# PIC32CM1216LS00064 device description
Architecture: CORTEX-M23; Family: PIC32CM; Series: PIC32CMLS00
Registers are 32-bit, read-write, reset 0x0 unless marked. A register's access mark holds for its fields unless they carry their own. Offsets are from the block's base; [hi:lo] are bit positions; {n}, {i} and the like mark numbered series; 'fields as' and 'values as' point back to an identical list; <NAME> marks a mode.

## DAC — Digital-to-Analog Converter
Instances: DAC 0x42003C00
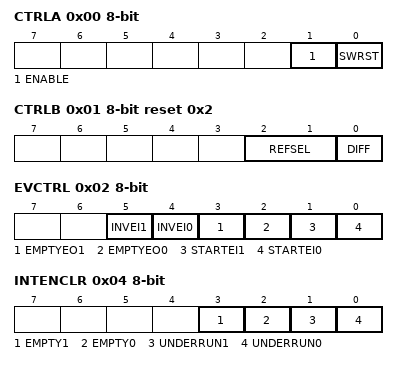
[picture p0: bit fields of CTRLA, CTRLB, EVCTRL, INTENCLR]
0x00 CTRLA 8-bit (WSYNC) — Control A
  [1] ENABLE — Enable DAC Controller
  [0] SWRST — Software Reset
0x01 CTRLB 8-bit reset 0x2 — Control B
  [2:1] REFSEL — Reference Selection for DAC0/1
    0=VREFAU (Unbuffered External Voltage Reference (not buffered in DAC, direct connection)); 1=VDDANA (Analog Voltage Supply); 2=VREFAB (Buffered External Voltage Reference (buffered in DAC)); 3=INTREF (Internal Voltage Reference)
  [0] DIFF — Differential mode enable
0x02 EVCTRL 8-bit — Event Control
  [5] INVEI1 — Enable Invertion of DAC 1 input event
  [4] INVEI0 — Enable Invertion of DAC 0 input event
  [3] EMPTYEO1 — Data Buffer Empty Event Output DAC 1
  [2] EMPTYEO0 — Data Buffer Empty Event Output DAC 0
  [1] STARTEI1 — Start Conversion Event Input DAC 1
  [0] STARTEI0 — Start Conversion Event Input DAC 0
0x04 INTENCLR 8-bit (atomic clear) — Interrupt Enable Clear
  [3] EMPTY1 — Data Buffer 1 Empty Interrupt Enable
  [2] EMPTY0 — Data Buffer 0 Empty Interrupt Enable
  [1] UNDERRUN1 — Underrun Interrupt Enable for DAC 1
  [0] UNDERRUN0 — Underrun Interrupt Enable for DAC 0
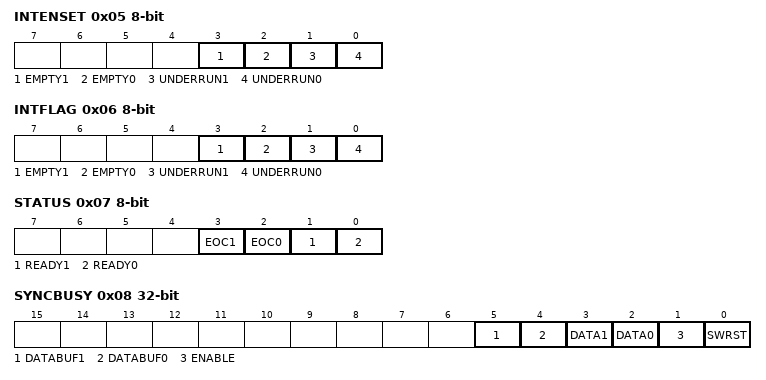
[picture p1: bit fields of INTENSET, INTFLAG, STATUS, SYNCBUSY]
0x05 INTENSET 8-bit (atomic set) — Interrupt Enable Set
  fields as INTENCLR
0x06 INTFLAG 8-bit (atomic clear) — Interrupt Flag Status and Clear
  [3] EMPTY1 — Data Buffer 1 Empty
  [2] EMPTY0 — Data Buffer 0 Empty
  [1] UNDERRUN1 — DAC 1 Underrun
  [0] UNDERRUN0 — DAC 0 Underrun
0x07 STATUS 8-bit ro
  [3] EOC1 — DAC 1 End of Conversion
  [2] EOC0 — DAC 0 End of Conversion
  [1] READY1 — DAC 1 Startup Ready
  [0] READY0 — DAC 0 Startup Ready
0x08 SYNCBUSY ro — Synchronization Busy
  [5] DATABUF1 — Data Buffer DAC 1
  [4] DATABUF0 — Data Buffer DAC 0
  [3] DATA1 — Data DAC 1
  [2] DATA0 — Data DAC 0
  [1] ENABLE — DAC Enable Status
  [0] SWRST — Software Reset
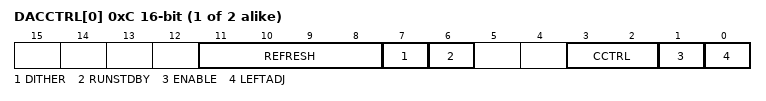
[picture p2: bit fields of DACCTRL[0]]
{0xC+2i} DACCTRL[{i}] (i=0..1) 16-bit — DAC n Control
  [11:8] REFRESH — Refresh period
    0=Do not Refresh; 2=Refresh every 60US; 3=Refresh every 90US; 4=Refresh every 120US; 5=Refresh every 150US; 6=Refresh every 180US; 7=Refresh every 210US; 8=Refresh every 240US; 9=Refresh every 270US; 10=Refresh every 300US; 11=Refresh every 330US; 12=Refresh every 360US; 13=Refresh every 390US; 14=Refresh every 420US; 15=Refresh every 450US
  [7] DITHER — Dithering Mode
  [6] RUNSTDBY — Run in Standby
  [3:2] CCTRL — Current Control
    0=CC100K (GCLK_DAC <= 1.2MHz (100kSPS)); 1=CC1M (1.2MHz < GCLK_DAC <= 6MHz (500kSPS)); 2=CC12M (6MHz < GCLK_DAC <= 12MHz (1MSPS))
  [1] ENABLE — Enable DAC0
  [0] LEFTADJ — Left Adjusted Data
{0x10+2i} DATA[{i}] (i=0..1) 16-bit wo (WSYNC) — DAC n Data
  [15:0] DATA — DAC0 Data
{0x14+2i} DATABUF[{i}] (i=0..1) 16-bit wo (WSYNC) — DAC n Data Buffer
  [15:0] DATABUF — DAC0 Data Buffer
0x18 DBGCTRL 8-bit — Debug Control
  [0] DBGRUN — Debug Run

## DIB — Debug Identification Block
Instances: DIB 0xE000EFB0, DIB_NS 0xE002EFB0
0x00 DLAR wo reset not defined — SCS Software Lock Access Register
  [31:0] KEY — Lock access control
    0xC5ACCE55=UNLOCK (Unlock key value)
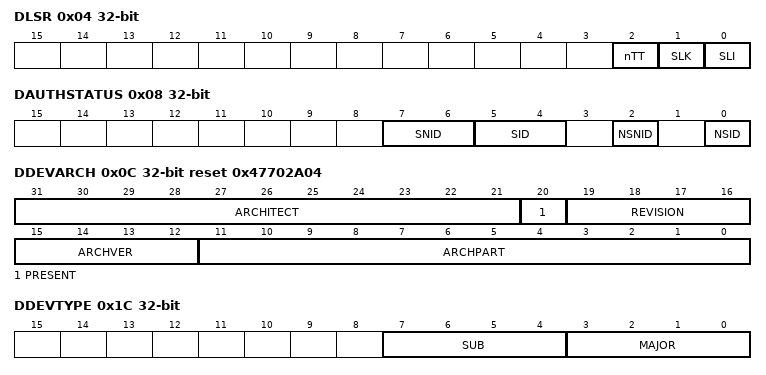
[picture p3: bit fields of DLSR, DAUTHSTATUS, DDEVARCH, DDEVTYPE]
0x04 DLSR ro reset not defined — SCS Software Lock Status Register
  [2] nTT — Not thirty-two bit
  [1] SLK — Software Lock status
  [0] SLI — Software Lock implemented
0x08 DAUTHSTATUS ro reset not defined — Debug Authentication Status Register
  [7:6] SNID
    0=NOSEC (Security Extension not implemented); 2=NO (Secure non-invasive debug prohibited); 3=YES (Secure non-invasive debug allowed)
  [5:4] SID
    0=NOSEC (Security Extension not implemented); 2=NO (Secure invasive debug prohibited); 3=YES (Secure invasive debug allowed)
  [2] NSNID
    2=NO (Non-secure non-invasive debug prohibited); 3=YES (Non-secure non-invasive debug allowed)
  [0] NSID
    2=NO (Non-secure invasive debug prohibited); 3=YES (Non-secure invasive debug allowed)
0x0C DDEVARCH ro reset 0x47702A04 — SCS Device Architecture Register
  [31:21] ARCHITECT
  [20] PRESENT — DEVARCH Present
  [19:16] REVISION
  [15:12] ARCHVER — Architecture Version
  [11:0] ARCHPART — Architecture Part
0x1C DDEVTYPE ro — SCS Device Type Register
  [7:4] SUB — Sub-type
  [3:0] MAJOR — Major type
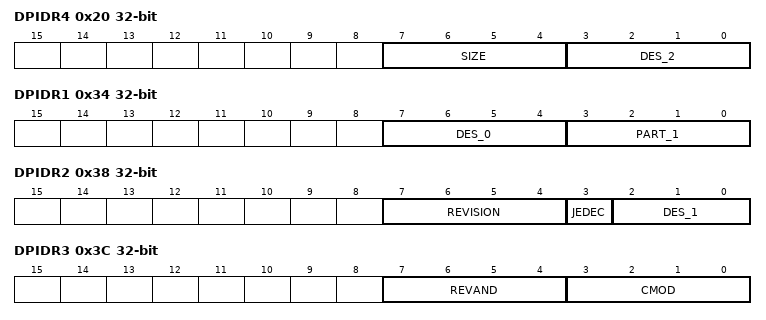
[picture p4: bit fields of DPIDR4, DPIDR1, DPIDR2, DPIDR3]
0x20 DPIDR4 ro reset not defined — SCS Peripheral Identification Register 4
  [7:4] SIZE — 4KB count
  [3:0] DES_2 — JEP106 continuation code
{0x10+4i} DPIDR{i} ro (i=5..7) — SCS Peripheral Identification Register {i}
0x30 DPIDR0 ro reset not defined — SCS Peripheral Identification Register 0
  [7:0] PART_0 — Part number bits[7:0]
0x34 DPIDR1 ro reset not defined — SCS Peripheral Identification Register 1
  [7:4] DES_0 — JEP106 identification code bits [3:0]
  [3:0] PART_1 — Part number bits[11:8]
0x38 DPIDR2 ro reset not defined — SCS Peripheral Identification Register 2
  [7:4] REVISION — Component revision
  [3] JEDEC — JEDEC assignee value is used
  [2:0] DES_1 — JEP106 identification code bits[6:4]
0x3C DPIDR3 ro reset not defined — SCS Peripheral Identification Register 3
  [7:4] REVAND
  [3:0] CMOD — Customer Modified
0x40 DCIDR0 ro reset 0xD — SCS Component Identification Register 0
  [7:0] PRMBL_0 — CoreSight component identification preamble
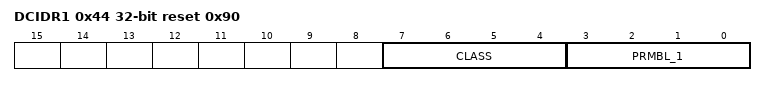
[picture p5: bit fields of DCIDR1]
0x44 DCIDR1 ro reset 0x90 — SCS Component Identification Register 1
  [7:4] CLASS — CoreSight component class
  [3:0] PRMBL_1 — CoreSight component identification preamble
0x48 DCIDR2 ro reset 0x5 — SCS Component Identification Register 2
  [7:0] PRMBL_2 — CoreSight component identification preamble
0x4C DCIDR3 ro reset 0xB1 — SCS Component Identification Register 3
  [7:0] PRMBL_3 — CoreSight component identification preamble

## Notices in the file
Copyright (c) 2019 Microchip Technology Inc.
SPDX-License-Identifier: Apache-2.0
Licensed under the Apache License, Version 2.0 (the "License");
you may not use this file except in compliance with the License.
You may obtain a copy of the License at
http://www.apache.org/licenses/LICENSE-2.0
Unless required by applicable law or agreed to in writing, software
distributed under the License is distributed on an "AS IS" BASIS,
WITHOUT WARRANTIES OR CONDITIONS OF ANY KIND, either express or implied.
See the License for the specific language governing permissions and
limitations under the License.
